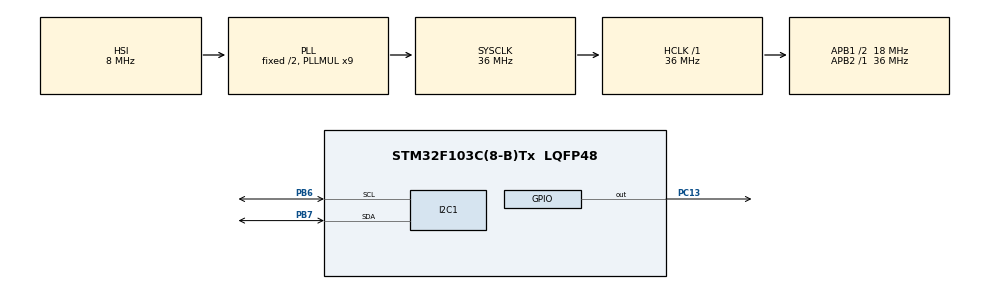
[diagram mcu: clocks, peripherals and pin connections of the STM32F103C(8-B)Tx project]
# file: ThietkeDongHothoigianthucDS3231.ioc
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Mcu.Family=STM32F1
Mcu.Name=STM32F103C(8-B)Tx
Mcu.Package=LQFP48
NVIC.PriorityGroup=NVIC_PRIORITYGROUP_4
PA13.Mode=Serial_Wire
PA13.Signal=SYS_JTMS-SWDIO
PA14.Mode=Serial_Wire
PA14.Signal=SYS_JTCK-SWCLK
PB6.Mode=I2C
PB6.Signal=I2C1_SCL
PB7.Mode=I2C
PB7.Signal=I2C1_SDA
PC13-TAMPER-RTC.Signal=GPIO_Output
ProjectManager.HeapSize=0x200
ProjectManager.StackSize=0x400
ProjectManager.TargetToolchain=MDK-ARM V5
RCC.AHBFreq_Value=36000000
RCC.APB1CLKDivider=RCC_HCLK_DIV2
RCC.APB1Freq_Value=18000000
RCC.APB1TimFreq_Value=36000000
RCC.APB2Freq_Value=36000000
RCC.APB2TimFreq_Value=36000000
RCC.HCLKFreq_Value=36000000
RCC.PLLMUL=RCC_PLL_MUL9
RCC.SYSCLKFreq_VALUE=36000000
RCC.SYSCLKSource=RCC_SYSCLKSOURCE_PLLCLK
RCC.USBFreq_Value=36000000
board=custom

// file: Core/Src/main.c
/* USER CODE BEGIN Header */
/**
  ******************************************************************************
  * @file           : main.c
  * @brief          : Main program body
  ******************************************************************************
  * @attention
  *
  * Copyright (c) 2023 STMicroelectronics.
  * All rights reserved.
  *
  * This software is licensed under terms that can be found in the LICENSE file
  * in the root directory of this software component.
  * If no LICENSE file comes with this software, it is provided AS-IS.
  *
  ******************************************************************************
  */
/* USER CODE END Header */
#include "main.h"

/* USER CODE BEGIN Includes */
#include <stdio.h>
//#include "CLCD_I2C.h"
#include "i2c-lcd.h"
/* USER CODE END Includes */

I2C_HandleTypeDef hi2c1;

/* USER CODE BEGIN PV */
#define DS3231_ADDRESS		(0x68<<1)     // I2C address; dich bit de lay dia chi chuan khung truyen
#define DS3231_REG_TIME    0x00					// thanh ghi dau tien cua ds3231 vs dia chi 0x00

typedef struct {
	uint8_t sec;
	uint8_t min;
	uint8_t hour;
	uint8_t day;
	uint8_t date;
	uint8_t month;
	uint8_t year;

	uint8_t I2C_Buffer[8];
}DS3231_t;

DS3231_t DS3231;

//CLCD_I2C_Name LCD1;
/* USER CODE END PV */

void SystemClock_Config(void);
static void MX_GPIO_Init(void);
static void MX_I2C1_Init(void);
/* USER CODE BEGIN PFP */
uint8_t RTC_BCD2DEC(uint8_t c);
uint8_t RTC_DEC2BCD(uint8_t c);
void RTC_SetTime(uint8_t hour, uint8_t min, uint8_t sec, uint8_t date, uint8_t day, uint8_t month, uint8_t year);
void RTC_GetTime(uint8_t *hour, uint8_t *min, uint8_t *sec, uint8_t *date, uint8_t *day, uint8_t *month, uint8_t *year);

/* USER CODE END PFP */

/* USER CODE BEGIN 0 */
uint8_t RTC_BCD2DEC(uint8_t c)  // chuyen doi BCD to DEC de doc data tu DS3231
{
	return (c>>4)*10 + (c&0x0f);

}
uint8_t RTC_DEC2BCD(uint8_t c)  // chuyen doi DEC to BCD de nap gia tri cho DS3231
{
	return (c/10)<<4|(c%10);
}

void RTC_SetTime(uint8_t hour, uint8_t min, uint8_t sec, uint8_t date ,uint8_t day, uint8_t month, uint8_t year)
{
	uint8_t Buf[7] = {RTC_DEC2BCD(sec),RTC_DEC2BCD(min),RTC_DEC2BCD(hour),RTC_DEC2BCD(date),
	RTC_DEC2BCD(day),RTC_DEC2BCD(month),RTC_DEC2BCD(year)};
	HAL_I2C_Mem_Write(&hi2c1,DS3231_ADDRESS,0x00,I2C_MEMADD_SIZE_8BIT,Buf,7,1000);

}

void RTC_GetTime(uint8_t *hour, uint8_t *min, uint8_t *sec, uint8_t *date, uint8_t *day, uint8_t *month, uint8_t *year)
{
	uint8_t Buf[8];
	HAL_I2C_Mem_Read(&hi2c1,DS3231_ADDRESS,0x00,I2C_MEMADD_SIZE_8BIT,Buf,7,100);
	*hour = RTC_BCD2DEC(Buf[2]);
	*min = RTC_BCD2DEC(Buf[1]);
	*sec = RTC_BCD2DEC(Buf[0]);
	*date = RTC_BCD2DEC(Buf[3]);
	*day = RTC_BCD2DEC(Buf[4]);
	*month = RTC_BCD2DEC(Buf[5]);
	*year = RTC_BCD2DEC(Buf[6]);

}

	char arr_str[20];
  char arr_str1[20];
/* USER CODE END 0 */

int main(void)
{

  /* MCU Configuration--------------------------------------------------------*/

  /* Reset of all peripherals, Initializes the Flash interface and the Systick. */
  HAL_Init();

  /* Configure the system clock */
  SystemClock_Config();

  /* Initialize all configured peripherals */
  MX_GPIO_Init();
  MX_I2C1_Init();
  /* USER CODE BEGIN 2 */
	//RTC_SetTime(12,30,0,25,2,23);
//	CLCD_I2C_Init(&LCD1, &hi2c1, 0x4e, 16,2);
//	CLCD_I2C_SetCursor(&LCD1, 0, 0);
//	CLCD_I2C_WriteString(&LCD1,"RTC CLOCK");
	lcd_init();
	lcd_goto_XY(1,0);
	lcd_send_string("Realtime Clock");
	lcd_goto_XY(2,0);
	lcd_send_string("Nhom 10");
	//RTC_SetTime(23,13,30,1,13,3,23);   // Gio/phut/giay/Ngay/Thu/Thang/Nam
	//rtc_write_time(22,35,12);
	HAL_Delay(2000);
  /* USER CODE END 2 */

  /* Infinite loop */
  /* USER CODE BEGIN WHILE */
  while (1)
  {
		//rtc_read_time(&a,&b,&c);
		RTC_GetTime(&DS3231.hour,&DS3231.min,&DS3231.sec,&DS3231.date,&DS3231.day,&DS3231.month,&DS3231.year);
		lcd_clear_display();
		lcd_goto_XY(1,0);
		sprintf(arr_str,"      %02d:%02d:%02d",DS3231.hour,DS3231.min,DS3231.sec);
		lcd_send_string(arr_str);
		lcd_goto_XY(2,3);
		sprintf(arr_str1,"%02d/%02d/%02d",DS3231.day,DS3231.month,DS3231.year +2000);
		lcd_send_string(arr_str1);
		HAL_GPIO_TogglePin(GPIOC,GPIO_PIN_13);
		HAL_Delay(1000);
    /* USER CODE END WHILE */

  }
}

void SystemClock_Config(void)
{
  RCC_OscInitTypeDef RCC_OscInitStruct = {0};
  RCC_ClkInitTypeDef RCC_ClkInitStruct = {0};

  /** Initializes the RCC Oscillators according to the specified parameters
  * in the RCC_OscInitTypeDef structure.
  */
  RCC_OscInitStruct.OscillatorType = RCC_OSCILLATORTYPE_HSI;
  RCC_OscInitStruct.HSIState = RCC_HSI_ON;
  RCC_OscInitStruct.HSICalibrationValue = RCC_HSICALIBRATION_DEFAULT;
  RCC_OscInitStruct.PLL.PLLState = RCC_PLL_ON;
  RCC_OscInitStruct.PLL.PLLSource = RCC_PLLSOURCE_HSI_DIV2;
  RCC_OscInitStruct.PLL.PLLMUL = RCC_PLL_MUL9;
  if (HAL_RCC_OscConfig(&RCC_OscInitStruct) != HAL_OK)
  {
    Error_Handler();
  }

  /** Initializes the CPU, AHB and APB buses clocks
  */
  RCC_ClkInitStruct.ClockType = RCC_CLOCKTYPE_HCLK|RCC_CLOCKTYPE_SYSCLK
                              |RCC_CLOCKTYPE_PCLK1|RCC_CLOCKTYPE_PCLK2;
  RCC_ClkInitStruct.SYSCLKSource = RCC_SYSCLKSOURCE_PLLCLK;
  RCC_ClkInitStruct.AHBCLKDivider = RCC_SYSCLK_DIV1;
  RCC_ClkInitStruct.APB1CLKDivider = RCC_HCLK_DIV2;
  RCC_ClkInitStruct.APB2CLKDivider = RCC_HCLK_DIV1;

  if (HAL_RCC_ClockConfig(&RCC_ClkInitStruct, FLASH_LATENCY_1) != HAL_OK)
  {
    Error_Handler();
  }
}

static void MX_I2C1_Init(void)
{

  hi2c1.Instance = I2C1;
  hi2c1.Init.ClockSpeed = 100000;
  hi2c1.Init.DutyCycle = I2C_DUTYCYCLE_2;
  hi2c1.Init.OwnAddress1 = 0;
  hi2c1.Init.AddressingMode = I2C_ADDRESSINGMODE_7BIT;
  hi2c1.Init.DualAddressMode = I2C_DUALADDRESS_DISABLE;
  hi2c1.Init.OwnAddress2 = 0;
  hi2c1.Init.GeneralCallMode = I2C_GENERALCALL_DISABLE;
  hi2c1.Init.NoStretchMode = I2C_NOSTRETCH_DISABLE;
  if (HAL_I2C_Init(&hi2c1) != HAL_OK)
  {
    Error_Handler();
  }

}

static void MX_GPIO_Init(void)
{
  GPIO_InitTypeDef GPIO_InitStruct = {0};

  /* GPIO Ports Clock Enable */
  __HAL_RCC_GPIOC_CLK_ENABLE();
  __HAL_RCC_GPIOA_CLK_ENABLE();
  __HAL_RCC_GPIOB_CLK_ENABLE();

  /*Configure GPIO pin Output Level */
  HAL_GPIO_WritePin(GPIOC, GPIO_PIN_13, GPIO_PIN_RESET);

  /*Configure GPIO pin : PC13 */
  GPIO_InitStruct.Pin = GPIO_PIN_13;
  GPIO_InitStruct.Mode = GPIO_MODE_OUTPUT_PP;
  GPIO_InitStruct.Pull = GPIO_NOPULL;
  GPIO_InitStruct.Speed = GPIO_SPEED_FREQ_LOW;
  HAL_GPIO_Init(GPIOC, &GPIO_InitStruct);

}

void Error_Handler(void)
{
  __disable_irq();
  while (1)
  {
  }
}
